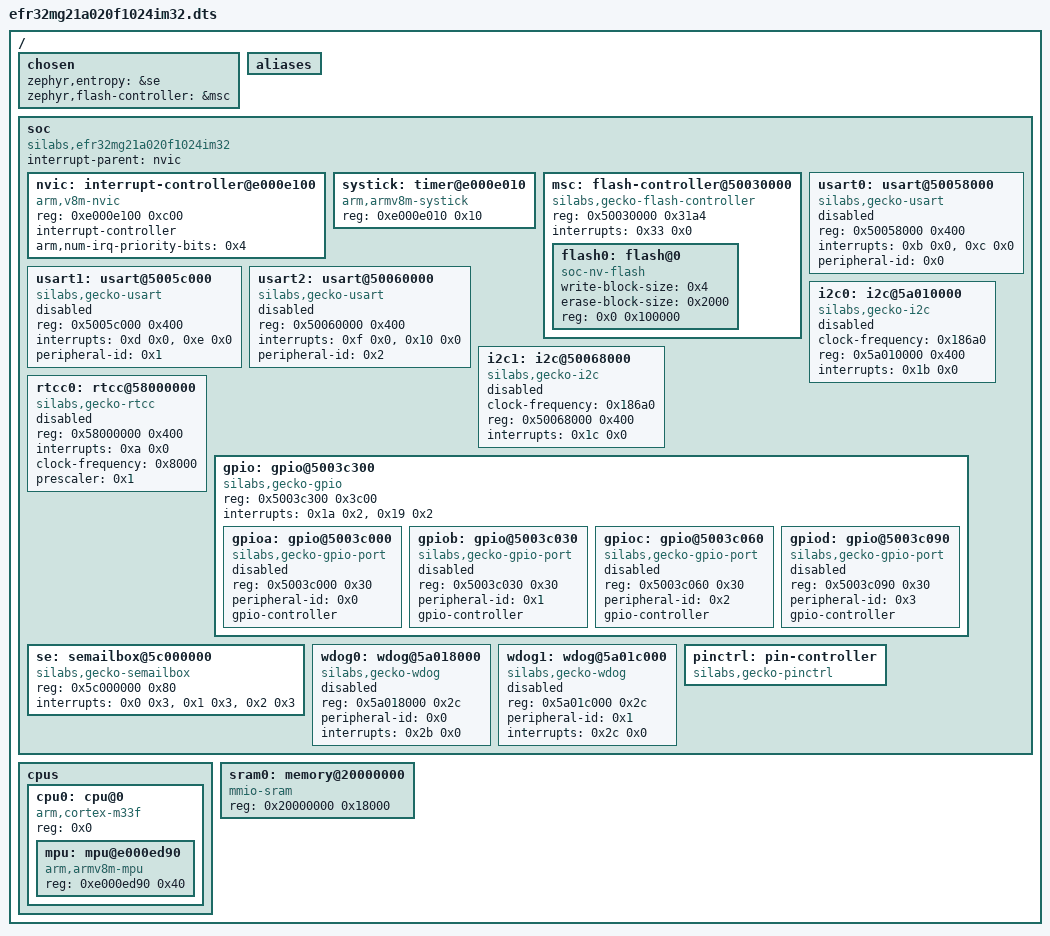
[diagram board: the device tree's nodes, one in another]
/dts-v1/;

/ {
	#address-cells = < 0x1 >;
	#size-cells = < 0x1 >;
	chosen {
		zephyr,entropy = &se;
		zephyr,flash-controller = &msc;
	};
	aliases {
	};
	soc {
		#address-cells = < 0x1 >;
		#size-cells = < 0x1 >;
		compatible = "silabs,efr32mg21a020f1024im32", "silabs,efr32mg21", "silabs,efr32", "simple-bus";
		interrupt-parent = < &nvic >;
		ranges;
		nvic: interrupt-controller@e000e100 {
			#address-cells = < 0x1 >;
			compatible = "arm,v8m-nvic";
			reg = < 0xe000e100 0xc00 >;
			interrupt-controller;
			#interrupt-cells = < 0x2 >;
			arm,num-irq-priority-bits = < 0x4 >;
			phandle = < 0x1 >;
		};
		systick: timer@e000e010 {
			compatible = "arm,armv8m-systick";
			reg = < 0xe000e010 0x10 >;
		};
		msc: flash-controller@50030000 {
			compatible = "silabs,gecko-flash-controller";
			reg = < 0x50030000 0x31a4 >;
			interrupts = < 0x33 0x0 >;
			#address-cells = < 0x1 >;
			#size-cells = < 0x1 >;
			flash0: flash@0 {
				compatible = "soc-nv-flash";
				write-block-size = < 0x4 >;
				erase-block-size = < 0x2000 >;
				reg = < 0x0 0x100000 >;
			};
		};
		usart0: usart@50058000 {
			compatible = "silabs,gecko-usart";
			reg = < 0x50058000 0x400 >;
			interrupts = < 0xb 0x0 >, < 0xc 0x0 >;
			interrupt-names = "rx", "tx";
			peripheral-id = < 0x0 >;
			status = "disabled";
		};
		usart1: usart@5005c000 {
			compatible = "silabs,gecko-usart";
			reg = < 0x5005c000 0x400 >;
			interrupts = < 0xd 0x0 >, < 0xe 0x0 >;
			interrupt-names = "rx", "tx";
			peripheral-id = < 0x1 >;
			status = "disabled";
		};
		usart2: usart@50060000 {
			compatible = "silabs,gecko-usart";
			reg = < 0x50060000 0x400 >;
			interrupts = < 0xf 0x0 >, < 0x10 0x0 >;
			interrupt-names = "rx", "tx";
			peripheral-id = < 0x2 >;
			status = "disabled";
		};
		i2c0: i2c@5a010000 {
			compatible = "silabs,gecko-i2c";
			clock-frequency = < 0x186a0 >;
			#address-cells = < 0x1 >;
			#size-cells = < 0x0 >;
			reg = < 0x5a010000 0x400 >;
			interrupts = < 0x1b 0x0 >;
			status = "disabled";
		};
		i2c1: i2c@50068000 {
			compatible = "silabs,gecko-i2c";
			clock-frequency = < 0x186a0 >;
			#address-cells = < 0x1 >;
			#size-cells = < 0x0 >;
			reg = < 0x50068000 0x400 >;
			interrupts = < 0x1c 0x0 >;
			status = "disabled";
		};
		rtcc0: rtcc@58000000 {
			compatible = "silabs,gecko-rtcc";
			reg = < 0x58000000 0x400 >;
			interrupts = < 0xa 0x0 >;
			clock-frequency = < 0x8000 >;
			prescaler = < 0x1 >;
			status = "disabled";
		};
		gpio: gpio@5003c300 {
			compatible = "silabs,gecko-gpio";
			reg = < 0x5003c300 0x3c00 >;
			interrupts = < 0x1a 0x2 >, < 0x19 0x2 >;
			interrupt-names = "GPIO_EVEN", "GPIO_ODD";
			ranges;
			#address-cells = < 0x1 >;
			#size-cells = < 0x1 >;
			gpioa: gpio@5003c000 {
				compatible = "silabs,gecko-gpio-port";
				reg = < 0x5003c000 0x30 >;
				peripheral-id = < 0x0 >;
				gpio-controller;
				#gpio-cells = < 0x2 >;
				status = "disabled";
			};
			gpiob: gpio@5003c030 {
				compatible = "silabs,gecko-gpio-port";
				reg = < 0x5003c030 0x30 >;
				peripheral-id = < 0x1 >;
				gpio-controller;
				#gpio-cells = < 0x2 >;
				status = "disabled";
			};
			gpioc: gpio@5003c060 {
				compatible = "silabs,gecko-gpio-port";
				reg = < 0x5003c060 0x30 >;
				peripheral-id = < 0x2 >;
				gpio-controller;
				#gpio-cells = < 0x2 >;
				status = "disabled";
			};
			gpiod: gpio@5003c090 {
				compatible = "silabs,gecko-gpio-port";
				reg = < 0x5003c090 0x30 >;
				peripheral-id = < 0x3 >;
				gpio-controller;
				#gpio-cells = < 0x2 >;
				status = "disabled";
			};
		};
		se: semailbox@5c000000 {
			compatible = "silabs,gecko-semailbox";
			reg = < 0x5c000000 0x80 >;
			interrupts = < 0x0 0x3 >, < 0x1 0x3 >, < 0x2 0x3 >;
			interrupt-names = "SETAMPERHOST", "SEMBRX", "SEMBTX";
			status = "okay";
		};
		wdog0: wdog@5a018000 {
			compatible = "silabs,gecko-wdog";
			reg = < 0x5a018000 0x2c >;
			peripheral-id = < 0x0 >;
			interrupts = < 0x2b 0x0 >;
			status = "disabled";
		};
		wdog1: wdog@5a01c000 {
			compatible = "silabs,gecko-wdog";
			reg = < 0x5a01c000 0x2c >;
			peripheral-id = < 0x1 >;
			interrupts = < 0x2c 0x0 >;
			status = "disabled";
		};
		pinctrl: pin-controller {
			compatible = "silabs,gecko-pinctrl";
		};
	};
	cpus {
		#address-cells = < 0x1 >;
		#size-cells = < 0x0 >;
		cpu0: cpu@0 {
			device_type = "cpu";
			compatible = "arm,cortex-m33f";
			reg = < 0x0 >;
			#address-cells = < 0x1 >;
			#size-cells = < 0x1 >;
			mpu: mpu@e000ed90 {
				compatible = "arm,armv8m-mpu";
				reg = < 0xe000ed90 0x40 >;
			};
		};
	};
	sram0: memory@20000000 {
		device_type = "memory";
		compatible = "mmio-sram";
		reg = < 0x20000000 0x18000 >;
	};
};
